# ATtiny2313 register map
Vendor: Atmel; File version: 1.0
CPU: other r0p0, little endian, no MPU, no FPU, 4 interrupt priority bits
Registers are 8-bit, read-write, reset 0x0 unless marked. A register's access mark holds for its fields unless they carry their own. Offsets are from the block's base; [hi:lo] are bit positions.

## EXINT — External Interrupts
Base 0x0000005A
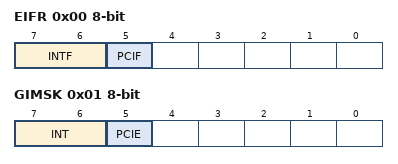
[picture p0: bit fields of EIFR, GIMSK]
0x00 EIFR — Extended Interrupt Flag Register
  [7:6] INTF — External Interrupt Flags
  [5] PCIF
0x01 GIMSK — General Interrupt Mask Register
  [7:6] INT — External Interrupt Request 1 Enable
  [5] PCIE

## FUSE — Fuses
Base 0x00000000
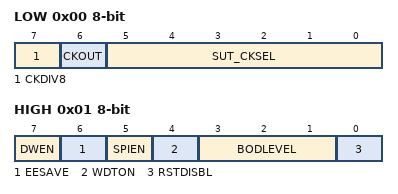
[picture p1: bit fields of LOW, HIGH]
0x00 LOW
  [7] CKDIV8 — Divide clock by 8 internally
  [6] CKOUT — Clock output on PORTD2
  [5:0] SUT_CKSEL — Select Clock Source
    0=EXTCLK_14CK_0MS (Ext. Clock; Start-up time: 14 CK + 0 ms); 2=INTRCOSC_4MHZ_14CK_0MS (Int. RC Osc. 4 MHz; Start-up time: 14 CK + 0 ms); 4=INTRCOSC_8MHZ_14CK_0MS (Int. RC Osc. 8 MHz; Start-up time: 14 CK + 0 ms); 6=INTRCOSC_128KHZ_14CK_0MS (Int. RC Osc. 128 kHz; Start-up time: 14 CK + 0 ms); 16=EXTCLK_14CK_4MS1 (Ext. Clock; Start-up time: 14 CK + 4.1 ms); 18=INTRCOSC_4MHZ_14CK_4MS1 (Int. RC Osc. 4 MHz; Start-up time: 14 CK + 4.1 ms); 20=INTRCOSC_8MHZ_14CK_4MS1 (Int. RC Osc. 8 MHz; Start-up time: 14 CK + 4.1 ms); 22=INTRCOSC_128KHZ_14CK_4MS (Int. RC Osc. 128 kHz; Start-up time: 14 CK + 4 ms); 25=EXTXOSC_0MHZ4_0MHZ9_14CK_0MS (Ext. Crystal Osc. 0.4-0.9 MHz; Start-up time: 14 CK + 0 ms); 27=EXTXOSC_0MHZ9_3MHZ_14CK_0MS (Ext. Crystal Osc. 0.9-3.0 MHz; Start-up time: 14 CK + 0 ms); 29=EXTXOSC_3MHZ_8MHZ_14CK_0MS (Ext. Crystal Osc. 3.0-8.0 MHz; Start-up time: 14 CK + 0 ms); 31=EXTXOSC_8MHZ_XX_14CK_0MS (Ext. Crystal Osc. 8.0- MHz; Start-up time: 14 CK + 0 ms); 32=EXTCLK_14CK_65MS (Ext. Clock; Start-up time: 14 CK + 65 ms); 34=INTRCOSC_4MHZ_14CK_65MS (Int. RC Osc. 4 MHz; Start-up time: 14 CK + 65 ms); 36=INTRCOSC_8MHZ_14CK_65MS (Int. RC Osc. 8 MHz; Start-up time: 14 CK + 65 ms); 38=INTRCOSC_128KHZ_14CK_64MS (Int. RC Osc. 128 kHz; Start-up time: 14 CK + 64 ms); 41=EXTXOSC_0MHZ4_0MHZ9_14CK_4MS1 (Ext. Crystal Osc. 0.4-0.9 MHz; Start-up time: 14 CK + 4.1 ms); 43=EXTXOSC_0MHZ9_3MHZ_14CK_4MS1 (Ext. Crystal Osc. 0.9-3.0 MHz; Start-up time: 14 CK + 4.1 ms); 45=EXTXOSC_3MHZ_8MHZ_14CK_4MS1 (Ext. Crystal Osc. 3.0-8.0 MHz; Start-up time: 14 CK + 4.1 ms); 47=EXTXOSC_8MHZ_XX_14CK_4MS1 (Ext. Crystal Osc. 8.0- MHz; Start-up time: 14 CK + 4.1 ms); 57=EXTXOSC_0MHZ4_0MHZ9_14CK_65MS (Ext. Crystal Osc. 0.4-0.9 MHz; Start-up time: 14 CK + 65 ms); 59=EXTXOSC_0MHZ9_3MHZ_14CK_65MS (Ext. Crystal Osc. 0.9-3.0 MHz; Start-up time: 14 CK + 65 ms); 61=EXTXOSC_3MHZ_8MHZ_14CK_65MS (Ext. Crystal Osc. 3.0-8.0 MHz; Start-up time: 14 CK + 65 ms); 63=EXTXOSC_8MHZ_XX_14CK_65MS (Ext. Crystal Osc. 8.0- MHz; Start-up time: 14 CK + 65 ms)
0x01 HIGH
  [7] DWEN — Debug Wire enable
  [6] EESAVE — Preserve EEPROM through the Chip Erase cycle
  [5] SPIEN — Serial program downloading (SPI) enable
  [4] WDTON — Watch-dog Timer always on
  [3:1] BODLEVEL — Brown-out Detector trigger level
    4=4V3 (Brown-out detection at VCC=4.3 V); 5=2V7 (Brown-out detection at VCC=2.7 V); 6=1V8 (Brown-out detection at VCC=1.8 V); 7=DISABLED (Brown-out detection disabled)
  [0] RSTDISBL — External reset disable
0x02 EXTENDED
  [0] SELFPRGEN — Self Programming enable

## LOCKBIT — Lockbits
Base 0x00000000
0x00 LOCKBIT
  [1:0] LB — Memory Lock
    0=PROG_VER_DISABLED (Further programming and verification disabled); 2=PROG_DISABLED (Further programming disabled); 3=NO_LOCK (No memory lock features enabled)

## PORTA — I/O Port
Base 0x00000039
0x00 PINA — Port A Input Pins
0x01 DDRA — Port A Data Direction Register
0x02 PORTA — Port A Data Register

## PORTB — I/O Port
Base 0x00000036
0x00 PINB — Port B Input Pins
0x01 DDRB — Port B Data Direction Register
0x02 PORTB — Port B Data Register

## PORTD — I/O Port
Base 0x00000030
0x00 PIND — Input Pins, Port D
0x01 DDRD — Data Direction Register, Port D
0x02 PORTD — Data Register, Port D
